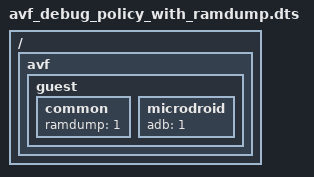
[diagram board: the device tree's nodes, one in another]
/dts-v1/;
/plugin/;

/ {
    fragment@avf {
        target-path = "/";

        __overlay__ {
            avf {
                guest {
                    common {
                        ramdump = <1>;
                    };
                    microdroid {
                        adb = <1>; // adb is required to check VM's bootargs.
                    };
                };
            };
        };
    };
};

